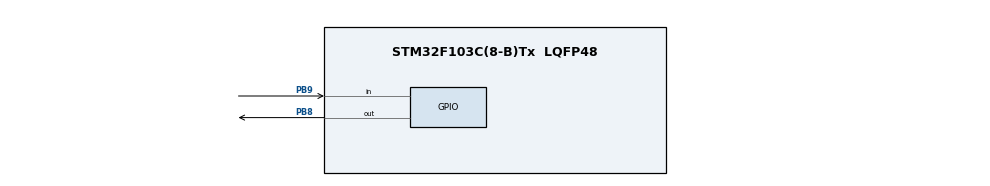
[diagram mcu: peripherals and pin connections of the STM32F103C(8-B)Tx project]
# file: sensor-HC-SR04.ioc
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Mcu.Family=STM32F1
Mcu.Name=STM32F103C(8-B)Tx
Mcu.Package=LQFP48
NVIC.PriorityGroup=NVIC_PRIORITYGROUP_4
PB8.Signal=GPIO_Output
PB9.GPIO_PuPd=GPIO_PULLDOWN
PB9.Signal=GPIO_Input
ProjectManager.HeapSize=0x200
ProjectManager.StackSize=0x400
ProjectManager.TargetToolchain=STM32CubeIDE
RCC.APB1Freq_Value=8000000
RCC.APB2Freq_Value=8000000
TIM2.Prescaler=800/1000000-1
VP_SYS_VS_ND.Mode=No_Debug
VP_TIM2_VS_ClockSourceINT.Mode=Internal
board=custom

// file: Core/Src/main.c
/* USER CODE BEGIN Header */
/**
  ******************************************************************************
  * @file           : main.c
  * @brief          : Main program body
  ******************************************************************************
  * @attention
  *
  * Copyright (c) 2025 STMicroelectronics.
  * All rights reserved.
  *
  * This software is licensed under terms that can be found in the LICENSE file
  * in the root directory of this software component.
  * If no LICENSE file comes with this software, it is provided AS-IS.
  *
  ******************************************************************************
  */
/* USER CODE END Header */
#include "main.h"

/* USER CODE BEGIN Includes */
#include <stdint.h>
#include <stdio.h>
/* USER CODE END Includes */

/* USER CODE BEGIN PD */
// Define GPIO pins for HC-SR04
#define HCSR04_TRIG_PORT GPIOB
#define HCSR04_TRIG_PIN GPIO_PIN_8
#define HCSR04_ECHO_PORT GPIOB
#define HCSR04_ECHO_PIN GPIO_PIN_9

// Define timer for measuring pulse duration
#define HCSR04_TIMER TIM2 // You can choose another timer

// Define timeout for echo pulse (in microseconds)
#define HCSR04_TIMEOUT_US 20000

/* USER CODE END PD */

TIM_HandleTypeDef htim2;

/* USER CODE BEGIN PV */

// Global variables
TIM_HandleTypeDef htim2;
volatile uint32_t echo_start_time = 0;
volatile uint32_t echo_end_time = 0;
volatile uint32_t distance_cm = 0;

/* USER CODE END PV */

void SystemClock_Config(void);
static void MX_GPIO_Init(void);
static void MX_TIM2_Init(void);

/* USER CODE BEGIN 0 */

// Function to initialize the HC-SR04 sensor
void HCSR04_Init(void) {
  GPIO_InitTypeDef GPIO_InitStruct = {0};
  TIM_ClockConfigTypeDef sClockSourceConfig = {0};
  TIM_MasterConfigTypeDef sMasterConfig = {0};

  // 1. Enable GPIO clocks
  __HAL_RCC_GPIOB_CLK_ENABLE();
  __HAL_RCC_TIM2_CLK_ENABLE(); // Enable timer clock

  // 2. Configure TRIG pin as output
  GPIO_InitStruct.Pin = HCSR04_TRIG_PIN;
  GPIO_InitStruct.Mode = GPIO_MODE_OUTPUT_PP;
  GPIO_InitStruct.Speed = GPIO_SPEED_FREQ_LOW;
  HAL_GPIO_Init(HCSR04_TRIG_PORT, &GPIO_InitStruct);

  // 3. Configure ECHO pin as input with pull-down (to avoid floating)
  GPIO_InitStruct.Pin = HCSR04_ECHO_PIN;
  GPIO_InitStruct.Mode = GPIO_MODE_INPUT;
  GPIO_InitStruct.Pull = GPIO_PULLDOWN;
  HAL_GPIO_Init(HCSR04_ECHO_PORT, &GPIO_InitStruct);

  // 4. Configure Timer for pulse measurement
  htim2.Instance = TIM2;
  htim2.Init.Prescaler = HAL_RCC_GetPCLK1Freq() / 1000000 - 1; // 1 MHz clock (1 us resolution)
  htim2.Init.CounterMode = TIM_COUNTERMODE_UP;
  htim2.Init.Period = 0xFFFF - 1; // Max period
  htim2.Init.ClockDivision = TIM_CLOCKDIVISION_DIV1;
  htim2.Init.RepetitionCounter = 0;
  htim2.Init.AutoReloadPreload = TIM_AUTORELOAD_PRELOAD_DISABLE;
  if (HAL_TIM_Base_Init(&htim2) != HAL_OK) {
      Error_Handler();
  }

  sClockSourceConfig.ClockSource = TIM_CLOCKSOURCE_INTERNAL;
  if (HAL_TIM_ConfigClockSource(&htim2, &sClockSourceConfig) != HAL_OK) {
      Error_Handler();
  }

  sMasterConfig.MasterOutputTrigger = TIM_TRGO_RESET;
  sMasterConfig.MasterSlaveMode = TIM_MASTERSLAVEMODE_DISABLE;
  if (HAL_TIMEx_MasterConfigSynchronization(&htim2, &sMasterConfig) != HAL_OK) {
      Error_Handler();
  }
}

// Function to trigger the HC-SR04 sensor and measure distance
uint32_t HCSR04_Read(void) {
  // 1. Trigger the sensor (10us pulse)
  HAL_GPIO_WritePin(HCSR04_TRIG_PORT, HCSR04_TRIG_PIN, GPIO_PIN_SET);
  HAL_Delay(1); // Minimum 10us trigger pulse
  HAL_GPIO_WritePin(HCSR04_TRIG_PORT, HCSR04_TRIG_PIN, GPIO_PIN_RESET);

  // 2. Wait for the ECHO pin to go HIGH with timeout
  uint32_t timeout = HCSR04_TIMEOUT_US;
  while (HAL_GPIO_ReadPin(HCSR04_ECHO_PORT, HCSR04_ECHO_PIN) == GPIO_PIN_RESET) {
      timeout--;
      if (timeout == 0) {
          return 0; // Timeout, no object detected or error
      }
      HAL_Delay(1); // Simple delay, consider using timer for more accurate timeout
  }

  // 3. Start the timer
  __HAL_TIM_SET_COUNTER(&htim2, 0);
  HAL_TIM_Base_Start(&htim2);

  // 4. Wait for the ECHO pin to go LOW with timeout
  timeout = HCSR04_TIMEOUT_US;
  while (HAL_GPIO_ReadPin(HCSR04_ECHO_PORT, HCSR04_ECHO_PIN) == GPIO_PIN_SET) {
      timeout--;
      if (timeout == 0) {
          HAL_TIM_Base_Stop(&htim2);
          return 0; // Timeout, potential error
      }
      HAL_Delay(1); // Simple delay, consider using timer for more accurate timeout
  }

  // 5. Stop the timer
  HAL_TIM_Base_Stop(&htim2);

  // 6. Read the elapsed time (in microseconds)
  uint32_t pulse_duration_us = __HAL_TIM_GET_COUNTER(&htim2);

  // 7. Calculate the distance (speed of sound in air is approx. 343 m/s or 0.0343 cm/us)
  distance_cm = (pulse_duration_us * 0.0343) / 2; // Divide by 2 because the sound travels to the object and back

  return distance_cm;
}

/* USER CODE END 0 */

int main(void)
{

  /* MCU Configuration--------------------------------------------------------*/

  /* Reset of all peripherals, Initializes the Flash interface and the Systick. */
  HAL_Init();

  /* Configure the system clock */
  SystemClock_Config();

  /* USER CODE BEGIN SysInit */
  HCSR04_Init();

  __HAL_RCC_GPIOA_CLK_ENABLE();
  GPIO_InitTypeDef GPIO_InitStruct_LED = {0};
  GPIO_InitStruct_LED.Pin = GPIO_PIN_5;
  GPIO_InitStruct_LED.Mode = GPIO_MODE_OUTPUT_PP;
  GPIO_InitStruct_LED.Speed = GPIO_SPEED_FREQ_LOW;
  HAL_GPIO_Init(GPIOA, &GPIO_InitStruct_LED);
  /* USER CODE END SysInit */

  /* Initialize all configured peripherals */
  MX_GPIO_Init();
  MX_TIM2_Init();

  /* Infinite loop */
  /* USER CODE BEGIN WHILE */
  while (1)
  {
    uint32_t distance = HCSR04_Read();
    if (distance > 0) {
        // Do something with the distance (e.g., print it, control something)
        printf("D=%dmm at %dms\r\n", distance, HAL_GetTick());
        HAL_GPIO_WritePin(GPIOA, GPIO_PIN_5, GPIO_PIN_SET); // Turn LED ON
    } else {
        printf("Error or No object detected\r\n");
        HAL_GPIO_WritePin(GPIOA, GPIO_PIN_5, GPIO_PIN_RESET); // Turn LED OFF
    }
    HAL_Delay(500); // Delay between readings
    /* USER CODE END WHILE */

  }
}

void SystemClock_Config(void)
{
  RCC_OscInitTypeDef RCC_OscInitStruct = {0};
  RCC_ClkInitTypeDef RCC_ClkInitStruct = {0};

  /** Initializes the RCC Oscillators according to the specified parameters
  * in the RCC_OscInitTypeDef structure.
  */
  RCC_OscInitStruct.OscillatorType = RCC_OSCILLATORTYPE_HSI;
  RCC_OscInitStruct.HSIState = RCC_HSI_ON;
  RCC_OscInitStruct.HSICalibrationValue = RCC_HSICALIBRATION_DEFAULT;
  RCC_OscInitStruct.PLL.PLLState = RCC_PLL_NONE;
  if (HAL_RCC_OscConfig(&RCC_OscInitStruct) != HAL_OK)
  {
    Error_Handler();
  }

  /** Initializes the CPU, AHB and APB buses clocks
  */
  RCC_ClkInitStruct.ClockType = RCC_CLOCKTYPE_HCLK|RCC_CLOCKTYPE_SYSCLK
                              |RCC_CLOCKTYPE_PCLK1|RCC_CLOCKTYPE_PCLK2;
  RCC_ClkInitStruct.SYSCLKSource = RCC_SYSCLKSOURCE_HSI;
  RCC_ClkInitStruct.AHBCLKDivider = RCC_SYSCLK_DIV1;
  RCC_ClkInitStruct.APB1CLKDivider = RCC_HCLK_DIV1;
  RCC_ClkInitStruct.APB2CLKDivider = RCC_HCLK_DIV1;

  if (HAL_RCC_ClockConfig(&RCC_ClkInitStruct, FLASH_LATENCY_0) != HAL_OK)
  {
    Error_Handler();
  }
}

static void MX_TIM2_Init(void)
{

  TIM_ClockConfigTypeDef sClockSourceConfig = {0};
  TIM_MasterConfigTypeDef sMasterConfig = {0};

  htim2.Instance = TIM2;
  htim2.Init.Prescaler = 800/1000000-1;
  htim2.Init.CounterMode = TIM_COUNTERMODE_UP;
  htim2.Init.Period = 65535;
  htim2.Init.ClockDivision = TIM_CLOCKDIVISION_DIV1;
  htim2.Init.AutoReloadPreload = TIM_AUTORELOAD_PRELOAD_DISABLE;
  if (HAL_TIM_Base_Init(&htim2) != HAL_OK)
  {
    Error_Handler();
  }
  sClockSourceConfig.ClockSource = TIM_CLOCKSOURCE_INTERNAL;
  if (HAL_TIM_ConfigClockSource(&htim2, &sClockSourceConfig) != HAL_OK)
  {
    Error_Handler();
  }
  sMasterConfig.MasterOutputTrigger = TIM_TRGO_RESET;
  sMasterConfig.MasterSlaveMode = TIM_MASTERSLAVEMODE_DISABLE;
  if (HAL_TIMEx_MasterConfigSynchronization(&htim2, &sMasterConfig) != HAL_OK)
  {
    Error_Handler();
  }

}

static void MX_GPIO_Init(void)
{
  GPIO_InitTypeDef GPIO_InitStruct = {0};

  /* GPIO Ports Clock Enable */
  __HAL_RCC_GPIOB_CLK_ENABLE();

  /*Configure GPIO pin Output Level */
  HAL_GPIO_WritePin(GPIOB, GPIO_PIN_8, GPIO_PIN_RESET);

  /*Configure GPIO pin : PB8 */
  GPIO_InitStruct.Pin = GPIO_PIN_8;
  GPIO_InitStruct.Mode = GPIO_MODE_OUTPUT_PP;
  GPIO_InitStruct.Pull = GPIO_NOPULL;
  GPIO_InitStruct.Speed = GPIO_SPEED_FREQ_LOW;
  HAL_GPIO_Init(GPIOB, &GPIO_InitStruct);

  /*Configure GPIO pin : PB9 */
  GPIO_InitStruct.Pin = GPIO_PIN_9;
  GPIO_InitStruct.Mode = GPIO_MODE_INPUT;
  GPIO_InitStruct.Pull = GPIO_PULLDOWN;
  HAL_GPIO_Init(GPIOB, &GPIO_InitStruct);

}

void Error_Handler(void)
{
  /* USER CODE BEGIN Error_Handler_Debug */
  /* User can add his own implementation to report the HAL error return state */
  __disable_irq();
  while (1) {
      // Blink an LED to indicate error (replace with your error handling)
      HAL_GPIO_WritePin(GPIOA, GPIO_PIN_5, GPIO_PIN_SET);
      HAL_Delay(200);
      HAL_GPIO_WritePin(GPIOA, GPIO_PIN_5, GPIO_PIN_RESET);
      HAL_Delay(200);
  }
  /* USER CODE END Error_Handler_Debug */
}
